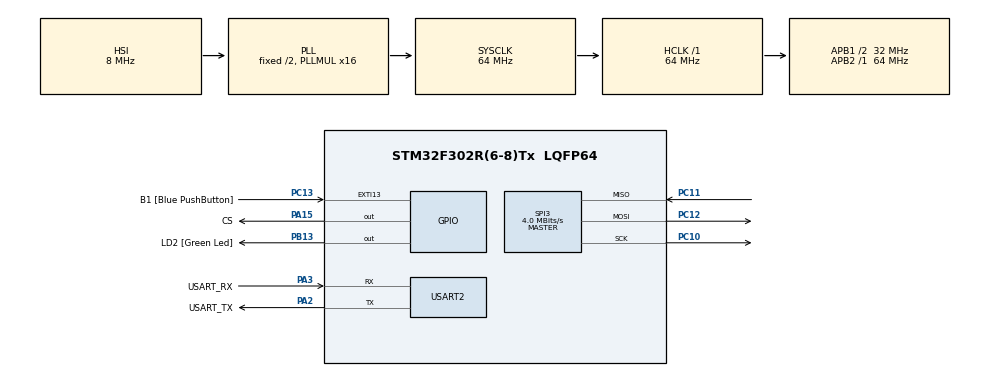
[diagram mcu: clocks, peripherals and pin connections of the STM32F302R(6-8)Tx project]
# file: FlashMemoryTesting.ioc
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Mcu.Family=STM32F3
Mcu.Name=STM32F302R(6-8)Tx
Mcu.Package=LQFP64
NVIC.PriorityGroup=NVIC_PRIORITYGROUP_0
PA13.GPIO_Label=TMS
PA13.Mode=Serial_Wire
PA13.Signal=SYS_JTMS-SWDIO
PA14.GPIO_Label=TCK
PA14.Mode=Serial_Wire
PA14.Signal=SYS_JTCK-SWCLK
PA15.GPIO_Label=CS
PA15.Signal=GPIO_Output
PA2.GPIO_Label=USART_TX
PA2.GPIO_Mode=GPIO_MODE_AF_PP
PA2.GPIO_PuPd=GPIO_NOPULL
PA2.GPIO_Speed=GPIO_SPEED_FREQ_LOW
PA2.Mode=Asynchronous
PA2.Signal=USART2_TX
PA3.GPIO_Label=USART_RX
PA3.GPIO_Mode=GPIO_MODE_AF_PP
PA3.GPIO_PuPd=GPIO_NOPULL
PA3.GPIO_Speed=GPIO_SPEED_FREQ_LOW
PA3.Mode=Asynchronous
PA3.Signal=USART2_RX
PB13.GPIO_Label=LD2 [Green Led]
PB13.Signal=GPIO_Output
PB3.GPIO_Label=SWO
PB3.Mode=Trace_Asynchronous_SW
PB3.Signal=SYS_JTDO-TRACESWO
PC10.Mode=Full_Duplex_Master
PC10.Signal=SPI3_SCK
PC11.Mode=Full_Duplex_Master
PC11.Signal=SPI3_MISO
PC12.Mode=Full_Duplex_Master
PC12.Signal=SPI3_MOSI
PC13.GPIO_Label=B1 [Blue PushButton]
PC13.GPIO_ModeDefaultEXTI=GPIO_MODE_IT_FALLING
PC13.Signal=GPXTI13
PC14\ -\ OSC32_IN.Mode=LSE-External-Oscillator
PC14\ -\ OSC32_IN.Signal=RCC_OSC32_IN
PC15\ -\ OSC32_OUT.Mode=LSE-External-Oscillator
PC15\ -\ OSC32_OUT.Signal=RCC_OSC32_OUT
PF0-OSC_IN.Mode=HSE-External-Oscillator
PF0-OSC_IN.Signal=RCC_OSC_IN
PF1-OSC_OUT.Mode=HSE-External-Oscillator
PF1-OSC_OUT.Signal=RCC_OSC_OUT
ProjectManager.HeapSize=0x200
ProjectManager.StackSize=0x400
ProjectManager.TargetToolchain=STM32CubeIDE
RCC.AHBFreq_Value=64000000
RCC.APB1CLKDivider=RCC_HCLK_DIV2
RCC.APB1Freq_Value=32000000
RCC.APB1TimFreq_Value=64000000
RCC.APB2Freq_Value=64000000
RCC.APB2TimFreq_Value=64000000
RCC.CortexFreq_Value=64000000
RCC.HCLKFreq_Value=64000000
RCC.HSE_VALUE=8000000
RCC.HSI_VALUE=8000000
RCC.PLLM=8
RCC.PLLMUL=RCC_PLL_MUL16
RCC.PLLN=336
RCC.PLLP=RCC_PLLP_DIV4
RCC.PLLQ=7
RCC.RCC_PLLsource_Clock_Source_FROM_HSE=RCC_HSE_PREDIV_DIV2
RCC.SYSCLKFreq_VALUE=64000000
RCC.SYSCLKSourceVirtual=RCC_SYSCLKSOURCE_PLLCLK
RCC.USBFreq_Value=64000000
SPI3.BaudRatePrescaler=SPI_BAUDRATEPRESCALER_8
SPI3.CalculateBaudRate=4.0 MBits/s
SPI3.DataSize=SPI_DATASIZE_8BIT
SPI3.Direction=SPI_DIRECTION_2LINES
SPI3.Mode=SPI_MODE_MASTER
SPI3.VirtualType=VM_MASTER
USART2.VirtualMode-Asynchronous=VM_ASYNC
board=NUCLEO-F302R8

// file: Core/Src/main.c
/* USER CODE BEGIN Header */
/**
  ******************************************************************************
  * @file           : main.c
  * @brief          : Main program body
  ******************************************************************************
  * @attention
  *
  * <h2><center>&copy; Copyright (c) 2022 STMicroelectronics.
  * All rights reserved.</center></h2>
  *
  * This software component is licensed by ST under BSD 3-Clause license,
  * the "License"; You may not use this file except in compliance with the
  * License. You may obtain a copy of the License at:
  *                        opensource.org/licenses/BSD-3-Clause
  *
  ******************************************************************************
  */
/* USER CODE END Header */
#include "main.h"

/* USER CODE BEGIN Includes */
#include "w25qxx.h"
/* USER CODE END Includes */

SPI_HandleTypeDef hspi3;

UART_HandleTypeDef huart2;

/* USER CODE BEGIN PV */
uint8_t writeBuffer[8] = {0, 1, 2, 3, 4, 5, 6, 7};
uint8_t readBuffer[8];
/* USER CODE END PV */

void SystemClock_Config(void);
static void MX_GPIO_Init(void);
static void MX_USART2_UART_Init(void);
static void MX_SPI3_Init(void);

int main(void)
{

  /* MCU Configuration--------------------------------------------------------*/

  /* Reset of all peripherals, Initializes the Flash interface and the Systick. */
  HAL_Init();

  /* Configure the system clock */
  SystemClock_Config();

  /* Initialize all configured peripherals */
  MX_GPIO_Init();
  MX_USART2_UART_Init();
  MX_SPI3_Init();
  /* USER CODE BEGIN 2 */
  W25qxx_Init();
  W25qxx_EraseChip();
  W25qxx_WriteSector(writeBuffer, 1, 0, 8);
  W25qxx_ReadSector(readBuffer, 1, 0, 8); //

  /* USER CODE END 2 */

  /* Infinite loop */
  while (1)
  {

  }
}

void SystemClock_Config(void)
{
  RCC_OscInitTypeDef RCC_OscInitStruct = {0};
  RCC_ClkInitTypeDef RCC_ClkInitStruct = {0};

  /** Initializes the RCC Oscillators according to the specified parameters
  * in the RCC_OscInitTypeDef structure.
  */
  RCC_OscInitStruct.OscillatorType = RCC_OSCILLATORTYPE_HSI;
  RCC_OscInitStruct.HSIState = RCC_HSI_ON;
  RCC_OscInitStruct.HSICalibrationValue = RCC_HSICALIBRATION_DEFAULT;
  RCC_OscInitStruct.PLL.PLLState = RCC_PLL_ON;
  RCC_OscInitStruct.PLL.PLLSource = RCC_PLLSOURCE_HSI;
  RCC_OscInitStruct.PLL.PLLMUL = RCC_PLL_MUL16;
  if (HAL_RCC_OscConfig(&RCC_OscInitStruct) != HAL_OK)
  {
    Error_Handler();
  }
  /** Initializes the CPU, AHB and APB buses clocks
  */
  RCC_ClkInitStruct.ClockType = RCC_CLOCKTYPE_HCLK|RCC_CLOCKTYPE_SYSCLK
                              |RCC_CLOCKTYPE_PCLK1|RCC_CLOCKTYPE_PCLK2;
  RCC_ClkInitStruct.SYSCLKSource = RCC_SYSCLKSOURCE_PLLCLK;
  RCC_ClkInitStruct.AHBCLKDivider = RCC_SYSCLK_DIV1;
  RCC_ClkInitStruct.APB1CLKDivider = RCC_HCLK_DIV2;
  RCC_ClkInitStruct.APB2CLKDivider = RCC_HCLK_DIV1;

  if (HAL_RCC_ClockConfig(&RCC_ClkInitStruct, FLASH_LATENCY_2) != HAL_OK)
  {
    Error_Handler();
  }
}

static void MX_SPI3_Init(void)
{

  /* SPI3 parameter configuration*/
  hspi3.Instance = SPI3;
  hspi3.Init.Mode = SPI_MODE_MASTER;
  hspi3.Init.Direction = SPI_DIRECTION_2LINES;
  hspi3.Init.DataSize = SPI_DATASIZE_8BIT;
  hspi3.Init.CLKPolarity = SPI_POLARITY_LOW;
  hspi3.Init.CLKPhase = SPI_PHASE_1EDGE;
  hspi3.Init.NSS = SPI_NSS_SOFT;
  hspi3.Init.BaudRatePrescaler = SPI_BAUDRATEPRESCALER_8;
  hspi3.Init.FirstBit = SPI_FIRSTBIT_MSB;
  hspi3.Init.TIMode = SPI_TIMODE_DISABLE;
  hspi3.Init.CRCCalculation = SPI_CRCCALCULATION_DISABLE;
  hspi3.Init.CRCPolynomial = 7;
  hspi3.Init.CRCLength = SPI_CRC_LENGTH_DATASIZE;
  hspi3.Init.NSSPMode = SPI_NSS_PULSE_ENABLE;
  if (HAL_SPI_Init(&hspi3) != HAL_OK)
  {
    Error_Handler();
  }

}

static void MX_USART2_UART_Init(void)
{

  huart2.Instance = USART2;
  huart2.Init.BaudRate = 38400;
  huart2.Init.WordLength = UART_WORDLENGTH_8B;
  huart2.Init.StopBits = UART_STOPBITS_1;
  huart2.Init.Parity = UART_PARITY_NONE;
  huart2.Init.Mode = UART_MODE_TX_RX;
  huart2.Init.HwFlowCtl = UART_HWCONTROL_NONE;
  huart2.Init.OverSampling = UART_OVERSAMPLING_16;
  huart2.Init.OneBitSampling = UART_ONE_BIT_SAMPLE_DISABLE;
  huart2.AdvancedInit.AdvFeatureInit = UART_ADVFEATURE_NO_INIT;
  if (HAL_UART_Init(&huart2) != HAL_OK)
  {
    Error_Handler();
  }

}

static void MX_GPIO_Init(void)
{
  GPIO_InitTypeDef GPIO_InitStruct = {0};

  /* GPIO Ports Clock Enable */
  __HAL_RCC_GPIOC_CLK_ENABLE();
  __HAL_RCC_GPIOF_CLK_ENABLE();
  __HAL_RCC_GPIOA_CLK_ENABLE();
  __HAL_RCC_GPIOB_CLK_ENABLE();

  /*Configure GPIO pin Output Level */
  HAL_GPIO_WritePin(LD2_GPIO_Port, LD2_Pin, GPIO_PIN_RESET);

  /*Configure GPIO pin Output Level */
  HAL_GPIO_WritePin(CS_GPIO_Port, CS_Pin, GPIO_PIN_RESET);

  /*Configure GPIO pin : B1_Pin */
  GPIO_InitStruct.Pin = B1_Pin;
  GPIO_InitStruct.Mode = GPIO_MODE_IT_FALLING;
  GPIO_InitStruct.Pull = GPIO_NOPULL;
  HAL_GPIO_Init(B1_GPIO_Port, &GPIO_InitStruct);

  /*Configure GPIO pin : LD2_Pin */
  GPIO_InitStruct.Pin = LD2_Pin;
  GPIO_InitStruct.Mode = GPIO_MODE_OUTPUT_PP;
  GPIO_InitStruct.Pull = GPIO_NOPULL;
  GPIO_InitStruct.Speed = GPIO_SPEED_FREQ_LOW;
  HAL_GPIO_Init(LD2_GPIO_Port, &GPIO_InitStruct);

  /*Configure GPIO pin : CS_Pin */
  GPIO_InitStruct.Pin = CS_Pin;
  GPIO_InitStruct.Mode = GPIO_MODE_OUTPUT_PP;
  GPIO_InitStruct.Pull = GPIO_NOPULL;
  GPIO_InitStruct.Speed = GPIO_SPEED_FREQ_LOW;
  HAL_GPIO_Init(CS_GPIO_Port, &GPIO_InitStruct);

}

void Error_Handler(void)
{
}

/************************ (C) COPYRIGHT STMicroelectronics *****END OF FILE****/
